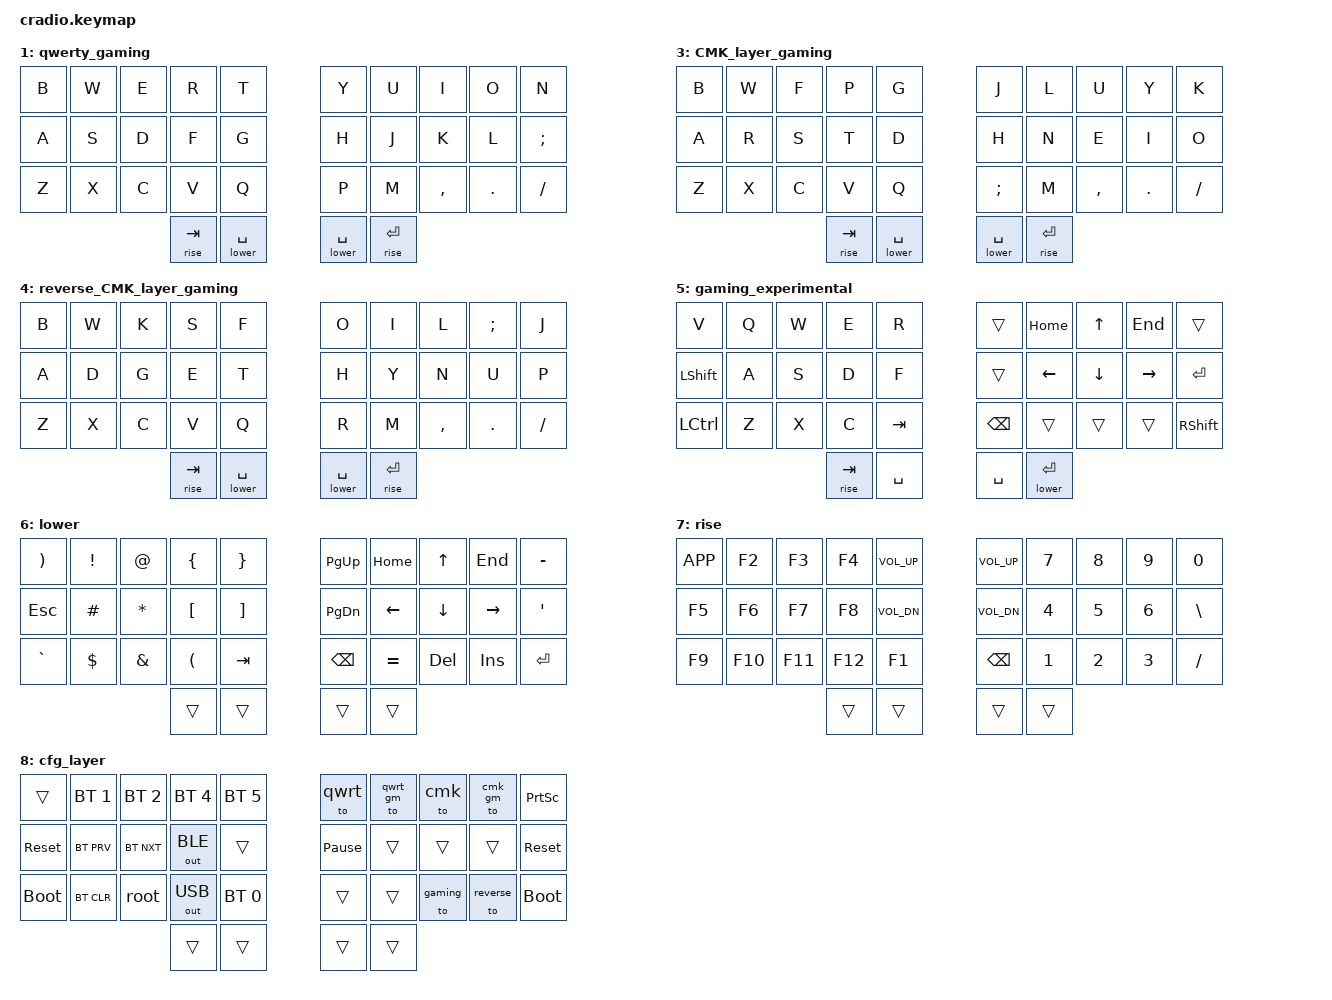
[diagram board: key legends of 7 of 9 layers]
/*
 * Copyright (c) 2020 The ZMK Contributors
 *
 * SPDX-License-Identifier: MIT
 */

#include <behaviors.dtsi>
#include <dt-bindings/zmk/bt.h>
#include <dt-bindings/zmk/keys.h>
#include <dt-bindings/zmk/outputs.h>

#define TAPPING_TERM 210
#define QUICK_TAP    150

#define ________ &trans

&lt {
	flavor = "hold-preferred";
	tapping-term-ms = <TAPPING_TERM>;
	quick-tap-ms = <QUICK_TAP>;
};

&mt {
	flavor = "balanced";
	tapping-term-ms = <TAPPING_TERM>;
	quick-tap-ms = <QUICK_TAP>;
};

&caps_word {
	continue-list = <UNDER MINUS BSPC RSHFT LSHFT>;
};

/ {
	behaviors {
		gresc: grave_escape {
			label = "grave_escape";
			compatible = "zmk,behavior-mod-morph";
			#binding-cells = <0>;
			mods = <(MOD_LGUI|MOD_RGUI)>;
			bindings = <&kp ESC>, <&kp GRAVE>;
		};
		ht: hold_tap {
			label = "hold_tap";
			compatible = "zmk,behavior-hold-tap";
			#binding-cells = <2>;
			flavor = "balanced";
			tapping-term-ms = <TAPPING_TERM>;
			quick-tap-ms = <QUICK_TAP>;
			global-quick-tap;
			bindings = <&kp>, <&kp>;
		};
		lht: left_positional_hold_tap {
			label = "left_positional_hold_tap";
			compatible = "zmk,behavior-hold-tap";
			#binding-cells = <2>;
			flavor = "balanced";
			tapping-term-ms = <TAPPING_TERM>;
			quick-tap-ms = <QUICK_TAP>;
			bindings = <&kp>, <&kp>;
			hold-trigger-key-positions = <
			0  1  2  3  4         5  6  7  8  9
			10 11 12 13 14        15 16 17 18 19
			20 21 22 23 24        25 26 27 28 29
						30 31  32 33>;
		};
		rht: right_positional_hold_tap {
			label = "right_positional_hold_tap";
			compatible = "zmk,behavior-hold-tap";
			#binding-cells = <2>;
			flavor = "balanced";
			tapping-term-ms = <TAPPING_TERM>;
			quick-tap-ms = <QUICK_TAP>;
			bindings = <&kp>, <&kp>;
			hold-trigger-key-positions = <
			0  1  2  3  4         5  6  7  8  9
			10 11 12 13 14        15 16 17 18 19
			20 21 22 23 24        25 26 27 28 29
						30 31  32 33>;
		};
	};
};

/ {
	macros {
		root: root {
			label = "root";
            compatible = "zmk,behavior-macro";
            #binding-cells = <0>;
            wait-ms = <1>;
            tap-ms = <1>;
			bindings 
			= <&macro_tap &kp O>
			, <&macro_tap &kp I>
			, <&macro_tap &kp U>
			, <&macro_tap &kp O>
			, <&macro_tap &kp I>
			, <&macro_tap &kp U>
			, <&macro_tap &kp O>
			, <&macro_tap &kp I>
			, <&macro_tap &kp U>
			, <&macro_tap &kp RET>
			;
		};
	};
};

#define qwrt 0
#define qwrt_gm 1
#define cmk 2
#define cmk_gm 3
#define reverse 4
#define gaming 5
#define lower 6
#define rise 7
#define cfg 8

#define HRML(k1,k2,k3,k4) &lht LGUI k1   &lht LALT k2   &lht LSHFT k3   &lht LCTRL k4
#define HRMR(k1,k2,k3,k4) &rht RCTRL k1  &rht RSHFT k2  &rht RALT k3    &rht RGUI k4

#define COMBO(name, keypress, keypos) \
combo_##name {                        \
	timeout-ms = <30>;                \
	bindings = <keypress>;            \
	key-positions = <keypos>;         \
};
/* Combo key positions
 0  1  2  3  4         5  6  7  8  9
10 11 12 13 14        15 16 17 18 19
20 21 22 23 24        25 26 27 28 29
			30 31  32 33             */

/ {
	combos {
		compatible = "zmk,combos";
		COMBO(lgui,     &kp LGUI,   20 21)
		COMBO(lalt,     &kp LALT,   21 22)
		COMBO(lshft,    &kp LSHFT,  22 23)
		COMBO(lctrl,    &kp LCTRL,  23 0)
		COMBO(rctrl,    &kp RCTRL,  9 26)
		COMBO(rshft,    &kp RSHFT,  26 27)
		COMBO(ralt,     &kp RALT,   27 28)
		COMBO(rgui,     &kp RGUI,   28 29)
		COMBO(cfg,      &mo cfg,    30 33)
		// COMBO(esc,      &kp ESC,    24 1)
		// COMBO(bspc,     &kp BSPC,   25 8)
	};
};


/ { 

        keymap {
                compatible = "zmk,keymap";
                
       	qwerty {
		bindings = <
		&kp B   &kp W   &kp E   &kp R   &kp T 					&kp Y   &kp U   &kp I       &kp O   &kp N 
		HRML(A,     S,      D,      F)  &kp G               	&kp H   HRMR(J,     K,          L,    SEMICOLON)
		&kp Z   &kp X   &kp C   &kp V   &kp Q					&kp P   &kp M   &kp CMMA    &kp DOT &kp FSLH
          				    &lt rise TAB   &lt lower SPACE		&lt lower SPACE     &lt rise RET 
		>;
		};

       	qwerty_gaming {
		bindings = <
		&kp B   &kp W   &kp E   &kp R   &kp T 				&kp Y   &kp U   &kp I       &kp O   &kp N
		&kp A   &kp S   &kp D   &kp F   &kp G               &kp H   &kp J   &kp K       &kp L   &kp SEMICOLON
		&kp Z   &kp X   &kp C   &kp V   &kp Q				&kp P   &kp M   &kp CMMA    &kp DOT &kp FSLH
          				    &lt rise TAB   &lt lower SPACE	&lt lower SPACE     &lt rise RET
		>;
		};

       	CMK_layer {
		bindings = <
		&kp B   &kp W   &kp F   &kp P   &kp G 				&kp J   &kp L   &kp U       &kp Y   &kp K
		HRML(A,     R,      S,      T)  &kp D               &kp H   HRMR(N,     E,          I,         O)
		&kp Z   &kp X   &kp C   &kp V   &kp Q				&kp SEMICOLON   &kp M   &kp CMMA    &kp DOT &kp FSLH
          				    &lt rise TAB   &lt lower SPACE	&lt lower SPACE     &lt rise RET 
		>;
		};

       	CMK_layer_gaming {
		bindings = <
		&kp B   &kp W   &kp F   &kp P   &kp G 				&kp J   &kp L   &kp U   &kp Y   &kp K
		&kp A   &kp R   &kp S   &kp T   &kp D               &kp H   &kp N   &kp E   &kp I   &kp O
		&kp Z   &kp X   &kp C   &kp V   &kp Q				&kp SEMICOLON   &kp M   &kp CMMA    &kp DOT &kp FSLH
          				    &lt rise TAB   &lt lower SPACE	&lt lower SPACE &lt rise RET
		>;
		};

       	reverse_CMK_layer_gaming {
		bindings = <
		&kp B   &kp W   &kp K	&kp S   &kp F 		&kp O   &kp	I   &kp L	 &kp SEMICOLON  &kp J
		&kp A   &kp D   &kp G   &kp E   &kp T       &kp	H  	&kp Y   &kp N	 &kp U   		&kp P
		&kp Z   &kp X   &kp C   &kp V	&kp Q		&kp R	&kp M   &kp CMMA &kp DOT 		&kp FSLH
          				    &lt rise TAB   &lt lower SPACE			&lt lower SPACE     &lt rise RET
		>;
		};

		gaming_experimental {
		bindings = <
		&kp V		&kp Q		&kp W		&kp E		&kp R				&trans 		&kp HOME	&kp UP		&kp END 	&trans 		
		&kp LSHFT	&kp A		&kp S		&kp D		&kp F				&trans 		&kp LEFT	&kp DOWN	&kp RIGHT	&kp RET		
		&kp LCTRL	&kp Z		&kp X		&kp C		&kp TAB				&kp BSPC	&trans 		&trans 		&trans 		&kp RSHFT
											&lt rise TAB &kp SPACE		&kp SPACE	&lt lower RET
		>;
		};

       	lower {
		bindings = <
        &kp RPAR    &kp EXCL    &kp AT      &kp LBRC    &kp RBRC        &kp PG_UP   &kp HOME    &kp UP      &kp END     &kp MINUS
        &kp ESC     &kp HASH    &kp ASTRK   &kp LBKT    &kp RBKT        &kp PG_DN   &kp LEFT    &kp DOWN    &kp RIGHT   &kp SQT
        &kp GRAVE   &kp DLLR    &kp AMPS    &kp LPAR    &kp TAB         &kp BSPC    &kp EQUAL   &kp DEL     &kp INS     &kp RET
					                        &trans 		&trans			&trans	  	&trans 
		>;
		};
		
		rise {
		bindings = <
	    &kp K_APP &kp F2	&kp F3 	&kp F4  &kp C_VOL_UP    &kp C_VOL_UP &kp N7 &kp N8	&kp N9  &kp N0
	    &kp F5    &kp F6    &kp F7  &kp F8  &kp C_VOL_DN    &kp C_VOL_DN &kp N4 &kp N5  &kp N6  &kp BSLH
	    &kp F9    &kp F10   &kp F11 &kp F12	&kp F1         	&kp BSPC     &kp N1 &kp N2  &kp N3	&kp FSLH
					  				&trans	&trans			&trans		 &trans	
		>;
		};	

		cfg_layer {
		bindings = <
		&trans	        &bt BT_SEL 1	&bt BT_SEL 2	&bt BT_SEL 4	&bt BT_SEL 5			&to qwrt 	    &to qwrt_gm &to cmk 	&to cmk_gm 	&kp PSCRN
		&sys_reset		&bt BT_PRV		&bt BT_NXT		&out OUT_BLE	&trans      	 		&kp PAUSE_BREAK &trans 		&trans 		&trans 		&sys_reset
		&bootloader		&bt BT_CLR		&root			&out OUT_USB	&bt BT_SEL 0    		&trans	    	&trans 		&to gaming 	&to reverse &bootloader
														&trans 			&trans 					&trans			&trans
		>;
		};	
        
	};
};

